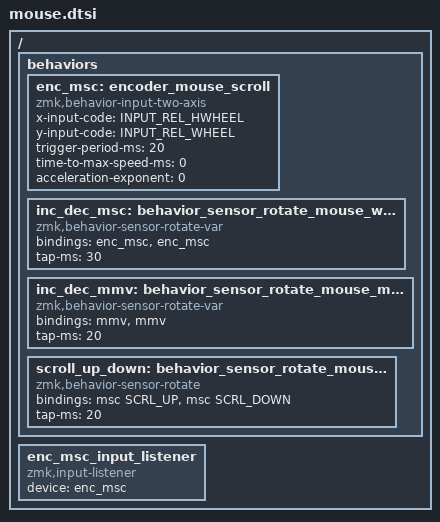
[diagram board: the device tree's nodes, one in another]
#define ZMK_MOUSE_SCRL_VAL_ENCODER 50
#define ZMK_POINTING_DEFAULT_MOVE_VAL 1500

#include <dt-bindings/zmk/pointing.h>
#include <zephyr/dt-bindings/input/input-event-codes.h>

#define SCRL_UP_ENCODER MOVE_Y(ZMK_MOUSE_SCRL_VAL_ENCODER)
#define SCRL_DOWN_ENCODER MOVE_Y(-ZMK_MOUSE_SCRL_VAL_ENCODER)
#define SCRL_LEFT_ENCODER MOVE_X(-ZMK_MOUSE_SCRL_VAL_ENCODER)
#define SCRL_RIGHT_ENCODER MOVE_X(ZMK_MOUSE_SCRL_VAL_ENCODER)

/ {
	behaviors {
		enc_msc: encoder_mouse_scroll {
			compatible = "zmk,behavior-input-two-axis";
			#binding-cells = <1>;
			x-input-code = <INPUT_REL_HWHEEL>;
			y-input-code = <INPUT_REL_WHEEL>;
			trigger-period-ms = <20>;
			time-to-max-speed-ms = <0>;
			acceleration-exponent = <0>;
		};

		inc_dec_msc: behavior_sensor_rotate_mouse_wheel {
			compatible = "zmk,behavior-sensor-rotate-var";
			#sensor-binding-cells = <2>;
			bindings = <&enc_msc>, <&enc_msc>;
			tap-ms = <30>;
		};

		inc_dec_mmv: behavior_sensor_rotate_mouse_movement {
			compatible = "zmk,behavior-sensor-rotate-var";
			#sensor-binding-cells = <2>;
			bindings = <&mmv>, <&mmv>;
			tap-ms = <20>;
		};

		scroll_up_down: behavior_sensor_rotate_mouse_wheel_up_down {
			compatible = "zmk,behavior-sensor-rotate";
			#sensor-binding-cells = <0>;
			bindings = <&msc SCRL_UP>, <&msc SCRL_DOWN>;
			tap-ms = <20>;
		};
	};

	enc_msc_input_listener: enc_msc_input_listener {
		compatible = "zmk,input-listener";
		device = <&enc_msc>;
	};
};
